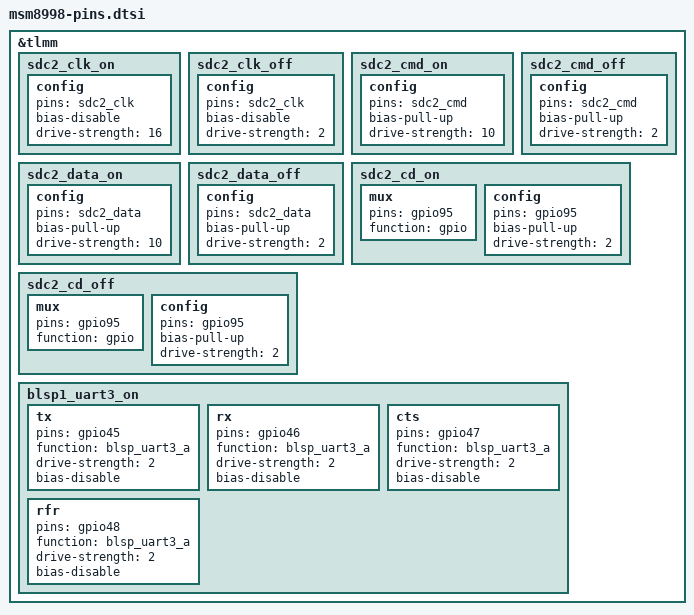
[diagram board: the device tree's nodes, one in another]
// SPDX-License-Identifier: GPL-2.0
/* Copyright (c) 2018, The Linux Foundation. All rights reserved. */

&tlmm {
	sdc2_clk_on: sdc2_clk_on {
		config {
			pins = "sdc2_clk";
			bias-disable;           /* NO pull */
			drive-strength = <16>;  /* 16 mA */
		};
	};

	sdc2_clk_off: sdc2_clk_off {
		config {
			pins = "sdc2_clk";
			bias-disable;           /* NO pull */
			drive-strength = <2>;   /* 2 mA */
		};
	};

	sdc2_cmd_on: sdc2_cmd_on {
		config {
			pins = "sdc2_cmd";
			bias-pull-up;           /* pull up */
			drive-strength = <10>;  /* 10 mA */
		};
	};

	sdc2_cmd_off: sdc2_cmd_off {
		config {
			pins = "sdc2_cmd";
			bias-pull-up;           /* pull up */
			drive-strength = <2>;   /* 2 mA */
		};
	};

	sdc2_data_on: sdc2_data_on {
		config {
			pins = "sdc2_data";
			bias-pull-up;           /* pull up */
			drive-strength = <10>;  /* 10 mA */
		};
	};

	sdc2_data_off: sdc2_data_off {
		config {
			pins = "sdc2_data";
			bias-pull-up;           /* pull up */
			drive-strength = <2>;   /* 2 mA */
		};
	};

	sdc2_cd_on: sdc2_cd_on {
		mux {
			pins = "gpio95";
			function = "gpio";
		};

		config {
			pins = "gpio95";
			bias-pull-up;           /* pull up */
			drive-strength = <2>;   /* 2 mA */
		};
	};

	sdc2_cd_off: sdc2_cd_off {
		mux {
			pins = "gpio95";
			function = "gpio";
		};

		config {
			pins = "gpio95";
			bias-pull-up;           /* pull up */
			drive-strength = <2>;   /* 2 mA */
		};
	};

	blsp1_uart3_on: blsp1_uart3_on {
		tx {
			pins = "gpio45";
			function = "blsp_uart3_a";
			drive-strength = <2>;
			bias-disable;
		};

		rx {
			pins = "gpio46";
			function = "blsp_uart3_a";
			drive-strength = <2>;
			bias-disable;
		};

		cts {
			pins = "gpio47";
			function = "blsp_uart3_a";
			drive-strength = <2>;
			bias-disable;
		};

		rfr {
			pins = "gpio48";
			function = "blsp_uart3_a";
			drive-strength = <2>;
			bias-disable;
		};
	};
};
